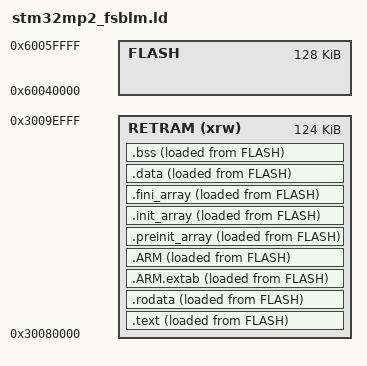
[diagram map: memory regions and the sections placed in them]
/*

Executes from 128 kiB RETRAM @ 0x30080000 (secure alias)
Save 4 kiB at end for stack

Add flash load address so J-Link can program properly

*/

ENTRY(Reset_Handler)

MEMORY
{
    RETRAM          (xrw) : ORIGIN = 0x30080000, LENGTH = 0x1f000
    FLASH                 : ORIGIN = 0x60040000, LENGTH = 0x20000
}

SECTIONS
{
  .text :
  {
    . = ALIGN(4);
    *(.text)           /* .text sections (code) */
    KEEP(*(.text.Reset_Handler)) /* Startup code */
    *(.text*)          /* .text* sections (code) */
    *(.glue_7)         /* glue arm to thumb code */
    *(.glue_7t)        /* glue thumb to arm code */
    *(.eh_frame)

    KEEP (*(.init))
    KEEP (*(.fini))

    . = ALIGN(4);
    _etext = .;        /* define a global symbols at end of code */
  } >RETRAM AT> FLASH

  .rodata :
  {
    . = ALIGN(4);
    *(.rodata)         /* .rodata sections (constants, strings, etc.) */
    *(.rodata*)        /* .rodata* sections (constants, strings, etc.) */
    . = ALIGN(4);
  } >RETRAM AT> FLASH

  .ARM.extab (READONLY) : /* The READONLY keyword is only supported in GCC11 and later, remove it if using GCC10 or earlier. */
  {
    . = ALIGN(4);
    *(.ARM.extab* .gnu.linkonce.armextab.*)
    . = ALIGN(4);
  } >RETRAM AT> FLASH

  .ARM (READONLY) : /* The READONLY keyword is only supported in GCC11 and later, remove it if using GCC10 or earlier. */
   {
    . = ALIGN(4);
    __exidx_start = .;
    *(.ARM.exidx*)
    __exidx_end = .;
    . = ALIGN(4);
  } >RETRAM AT> FLASH

  .preinit_array  (READONLY) : /* The READONLY keyword is only supported in GCC11 and later, remove it if using GCC10 or earlier. */
  {
    . = ALIGN(4);
    PROVIDE_HIDDEN (__preinit_array_start = .);
    KEEP (*(.preinit_array*))
    PROVIDE_HIDDEN (__preinit_array_end = .);
    . = ALIGN(4);
  } >RETRAM AT> FLASH

  .init_array (READONLY) : /* The READONLY keyword is only supported in GCC11 and later, remove it if using GCC10 or earlier. */
  {
    . = ALIGN(4);
    PROVIDE_HIDDEN (__init_array_start = .);
    KEEP (*(SORT(.init_array.*)))
    KEEP (*(.init_array*))
    PROVIDE_HIDDEN (__init_array_end = .);
    . = ALIGN(4);
  } >RETRAM AT> FLASH

  .fini_array (READONLY) : /* The READONLY keyword is only supported in GCC11 and later, remove it if using GCC10 or earlier. */
  {
    . = ALIGN(4);
    PROVIDE_HIDDEN (__fini_array_start = .);
    KEEP (*(SORT(.fini_array.*)))
    KEEP (*(.fini_array*))
    PROVIDE_HIDDEN (__fini_array_end = .);
    . = ALIGN(4);
  } >RETRAM AT> FLASH

  .data :
  {
    . = ALIGN(4);
    _sdata = .;        /* create a global symbol at data start */
    *(.data)           /* .data sections */
    *(.data*)          /* .data* sections */
    *(.RamFunc)        /* .RamFunc sections */
    *(.RamFunc*)       /* .RamFunc* sections */
    . = ALIGN(4);
    _edata = .;        /* define a global symbol at data end */

  } >RETRAM AT> FLASH

  . = ALIGN(4);
  .bss :
  {
    /* This is used by the startup in order to initialize the .bss section */
    _sbss = .;         /* define a global symbol at bss start */
    __bss_start__ = _sbss;
    *(.bss)
    *(.bss*)
    *(COMMON)

    . = ALIGN(4);
    _ebss = .;         /* define a global symbol at bss end */
    __bss_end__ = _ebss;
  } >RETRAM AT> FLASH

  _estack = 0x300a0000;
}
